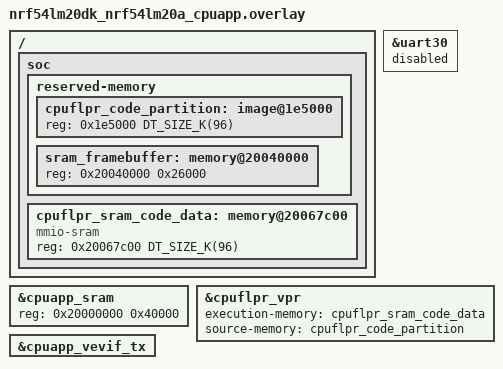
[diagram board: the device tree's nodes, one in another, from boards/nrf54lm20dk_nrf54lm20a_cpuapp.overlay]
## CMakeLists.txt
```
#
# Copyright (c) 2022 Nordic Semiconductor ASA
#
# SPDX-License-Identifier: LicenseRef-Nordic-5-Clause
#

cmake_minimum_required(VERSION 3.20.0)

find_package(Zephyr REQUIRED HINTS $ENV{ZEPHYR_BASE})
project(displaytest)

target_sources(app PRIVATE
    src/main.c
    src/render.c
    src/game.c
)

target_include_directories(app PRIVATE ${CMAKE_CURRENT_LIST_DIR}/../common)
```

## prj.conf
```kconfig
CONFIG_GPIO=y
CONFIG_SERIAL=y
CONFIG_CONSOLE=y
CONFIG_UART_CONSOLE=y

# Floating point support for game physics
CONFIG_FPU=y

# Increase main stack for game state + rendering
CONFIG_MAIN_STACK_SIZE=8192
```

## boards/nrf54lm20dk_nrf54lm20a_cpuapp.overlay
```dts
/*
 * CPU App overlay for nRF54LM20-DK Asteroids
 *
 * Based on the nordic-flpr snippet for nRF54LM20A, with additions
 * for the shared framebuffer region.
 *
 * Memory map:
 *   0x20000000 - 0x2003FFFF : CPUAPP SRAM (256KB) - kernel + game
 *   0x20040000 - 0x20065FFF : Shared framebuffer (155KB)
 *   0x20067C00 - 0x2007FBFF : FLPR SRAM (96KB) - display driver
 *
 *   0x001E5000 - 0x001FCFFF : FLPR code partition in RRAM (96KB)
 */

/ {
	soc {
		reserved-memory {
			#address-cells = <1>;
			#size-cells = <1>;

			/* FLPR firmware stored in RRAM (flash) - VPR launcher copies from here */
			cpuflpr_code_partition: image@1e5000 {
				reg = <0x1e5000 DT_SIZE_K(96)>;
			};

			/* Shared framebuffer between CPU and FLPR */
			sram_framebuffer: memory@20040000 {
				reg = <0x20040000 0x26000>;
			};
		};

		/* FLPR execution SRAM - VPR launcher loads code here */
		cpuflpr_sram_code_data: memory@20067c00 {
			compatible = "mmio-sram";
			reg = <0x20067c00 DT_SIZE_K(96)>;
			#address-cells = <1>;
			#size-cells = <1>;
			ranges = <0x0 0x20067c00 DT_SIZE_K(96)>;
		};
	};
};

/* Reduce CPUAPP SRAM: 256KB for kernel+game, rest is framebuffer + FLPR */
&cpuapp_sram {
	reg = <0x20000000 0x40000>;
	ranges = <0x0 0x20000000 0x40000>;
};

/* Reserve UART30 for FLPR console */
&uart30 {
	status = "reserved";
};

/* Enable FLPR core with memory configuration for VPR launcher */
&cpuflpr_vpr {
	status = "okay";
	execution-memory = <&cpuflpr_sram_code_data>;
	source-memory = <&cpuflpr_code_partition>;
};

/* Enable VEVIF TX for CPU->FLPR signaling (needed for VPR launcher) */
&cpuapp_vevif_tx {
	status = "okay";
};
```

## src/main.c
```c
/*
 * Asteroids - nRF54LM20-DK
 *
 * Main game loop on CPU (ARM Cortex-M33).
 * Interrupt-driven buttons, dirty-row framebuffer streaming via FLPR.
 */

#include <zephyr/kernel.h>
#include <zephyr/drivers/gpio.h>

#include "shared_display.h"
#include "game.h"
#include "render.h"

/* ------------------------------------------------------------------ */
/*  Interrupt-driven buttons                                          */
/* ------------------------------------------------------------------ */

static const struct gpio_dt_spec btn_specs[] = {
	GPIO_DT_SPEC_GET(DT_ALIAS(sw0), gpios),
	GPIO_DT_SPEC_GET(DT_ALIAS(sw1), gpios),
	GPIO_DT_SPEC_GET(DT_ALIAS(sw2), gpios),
	GPIO_DT_SPEC_GET(DT_ALIAS(sw3), gpios),
};

static struct gpio_callback btn_cb_data[4];
static volatile uint8_t button_state;

static void btn_isr(const struct device *dev, struct gpio_callback *cb, uint32_t pins)
{
	uint8_t state = 0;
	if (gpio_pin_get_dt(&btn_specs[0])) state |= BTN_THRUST;
	if (gpio_pin_get_dt(&btn_specs[1])) state |= BTN_LEFT;
	if (gpio_pin_get_dt(&btn_specs[2])) state |= BTN_RIGHT;
	if (gpio_pin_get_dt(&btn_specs[3])) state |= BTN_SHOOT;
	button_state = state;
}

static int init_buttons(void)
{
	for (int i = 0; i < ARRAY_SIZE(btn_specs); i++) {
		if (!gpio_is_ready_dt(&btn_specs[i])) {
			printk("ERROR: Button %d not ready\n", i);
			return -1;
		}
		int ret = gpio_pin_configure_dt(&btn_specs[i], GPIO_INPUT);
		if (ret < 0) return ret;

		ret = gpio_pin_interrupt_configure_dt(&btn_specs[i],
						      GPIO_INT_EDGE_BOTH);
		if (ret < 0) {
			printk("WARN: Button %d interrupt failed (%d), using polled\n", i, ret);
			continue;
		}

		gpio_init_callback(&btn_cb_data[i], btn_isr,
				   BIT(btn_specs[i].pin));
		gpio_add_callback(btn_specs[i].port, &btn_cb_data[i]);
	}
	return 0;
}

/* ------------------------------------------------------------------ */
/*  Display sync                                                      */
/* ------------------------------------------------------------------ */

static void wait_display_ready(void)
{
	printk("Waiting for FLPR...\n");
	while (SHARED_DISP->status == DISP_STATUS_INIT) {
		k_msleep(10);
	}
	printk("Display ready\n");
}

static void send_frame(void)
{
	/* Commit dirty bitmap to shared memory */
	render_commit_dirty();

	/* Memory barrier: ensure all framebuffer + dirty bitmap writes
	 * are committed before the FLPR sees FRAME_READY */
	__DSB();

	/* Signal FLPR */
	SHARED_DISP->status = DISP_STATUS_FRAME_READY;

	/* Tight spin — CPU has nothing else to do until FLPR finishes */
	while (SHARED_DISP->status != DISP_STATUS_READY) { }
}

/* ------------------------------------------------------------------ */
/*  Main                                                              */
/* ------------------------------------------------------------------ */

static struct game_state game;

int main(void)
{
	if (init_buttons() < 0) {
		return -1;
	}

	wait_display_ready();
	render_init(SHARED_DISP->framebuffer);
	render_set_mode(RMODE_PIXELS);  /* Change to RMODE_ROWS, RMODE_TILES or RMODE_PIXELS to test */
	game_init(&game);

	while (1) {
		uint32_t frame_start = k_uptime_get_32();

		uint8_t btns = button_state;
		game_update(&game, btns);
		game_render(&game);

		/* Measure CPU work time (game logic + rendering) */
		uint32_t work_ms = k_uptime_get_32() - frame_start;
		SHARED_DISP->cpu_work_us = (uint16_t)(work_ms * 1000);

		send_frame();

		uint32_t elapsed = k_uptime_get_32() - frame_start;
		if (elapsed < FRAME_TIME_MS) {
			k_msleep(FRAME_TIME_MS - elapsed);
		}
	}

	return 0;
}
```

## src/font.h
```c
/*
 * 8x8 bitmap font for retro game rendering.
 * Covers printable ASCII (space through tilde, 32-126).
 * Each glyph is 8 bytes, one byte per row, MSB = leftmost pixel.
 *
 * Index into font_8x8[ch - 32] to get the glyph for character ch.
 */

#ifndef FONT_H
#define FONT_H

#include <stdint.h>

/* 95 printable ASCII characters (32=' ' through 126='~') */
static const uint8_t font_8x8[95][8] = {
	/* 32 ' ' */ {0x00,0x00,0x00,0x00,0x00,0x00,0x00,0x00},
	/* 33 '!' */ {0x18,0x18,0x18,0x18,0x18,0x00,0x18,0x00},
	/* 34 '"' */ {0x6C,0x6C,0x6C,0x00,0x00,0x00,0x00,0x00},
	/* 35 '#' */ {0x6C,0x6C,0xFE,0x6C,0xFE,0x6C,0x6C,0x00},
	/* 36 '$' */ {0x18,0x7E,0xC0,0x7C,0x06,0xFC,0x18,0x00},
	/* 37 '%' */ {0x00,0xC6,0xCC,0x18,0x30,0x66,0xC6,0x00},
	/* 38 '&' */ {0x38,0x6C,0x38,0x76,0xDC,0xCC,0x76,0x00},
	/* 39 '\''*/ {0x18,0x18,0x30,0x00,0x00,0x00,0x00,0x00},
	/* 40 '(' */ {0x0C,0x18,0x30,0x30,0x30,0x18,0x0C,0x00},
	/* 41 ')' */ {0x30,0x18,0x0C,0x0C,0x0C,0x18,0x30,0x00},
	/* 42 '*' */ {0x00,0x66,0x3C,0xFF,0x3C,0x66,0x00,0x00},
	/* 43 '+' */ {0x00,0x18,0x18,0x7E,0x18,0x18,0x00,0x00},
	/* 44 ',' */ {0x00,0x00,0x00,0x00,0x00,0x18,0x18,0x30},
	/* 45 '-' */ {0x00,0x00,0x00,0x7E,0x00,0x00,0x00,0x00},
	/* 46 '.' */ {0x00,0x00,0x00,0x00,0x00,0x18,0x18,0x00},
	/* 47 '/' */ {0x06,0x0C,0x18,0x30,0x60,0xC0,0x80,0x00},
	/* 48 '0' */ {0x7C,0xC6,0xCE,0xDE,0xF6,0xE6,0x7C,0x00},
	/* 49 '1' */ {0x18,0x38,0x78,0x18,0x18,0x18,0x7E,0x00},
	/* 50 '2' */ {0x7C,0xC6,0x06,0x1C,0x30,0x66,0xFE,0x00},
	/* 51 '3' */ {0x7C,0xC6,0x06,0x3C,0x06,0xC6,0x7C,0x00},
	/* 52 '4' */ {0x1C,0x3C,0x6C,0xCC,0xFE,0x0C,0x1E,0x00},
	/* 53 '5' */ {0xFE,0xC0,0xFC,0x06,0x06,0xC6,0x7C,0x00},
	/* 54 '6' */ {0x38,0x60,0xC0,0xFC,0xC6,0xC6,0x7C,0x00},
	/* 55 '7' */ {0xFE,0xC6,0x0C,0x18,0x30,0x30,0x30,0x00},
	/* 56 '8' */ {0x7C,0xC6,0xC6,0x7C,0xC6,0xC6,0x7C,0x00},
	/* 57 '9' */ {0x7C,0xC6,0xC6,0x7E,0x06,0x0C,0x78,0x00},
	/* 58 ':' */ {0x00,0x18,0x18,0x00,0x00,0x18,0x18,0x00},
	/* 59 ';' */ {0x00,0x18,0x18,0x00,0x00,0x18,0x18,0x30},
	/* 60 '<' */ {0x06,0x0C,0x18,0x30,0x18,0x0C,0x06,0x00},
	/* 61 '=' */ {0x00,0x00,0x7E,0x00,0x7E,0x00,0x00,0x00},
	/* 62 '>' */ {0x60,0x30,0x18,0x0C,0x18,0x30,0x60,0x00},
	/* 63 '?' */ {0x7C,0xC6,0x0C,0x18,0x18,0x00,0x18,0x00},
	/* 64 '@' */ {0x7C,0xC6,0xDE,0xDE,0xDE,0xC0,0x78,0x00},
	/* 65 'A' */ {0x38,0x6C,0xC6,0xC6,0xFE,0xC6,0xC6,0x00},
	/* 66 'B' */ {0xFC,0x66,0x66,0x7C,0x66,0x66,0xFC,0x00},
	/* 67 'C' */ {0x3C,0x66,0xC0,0xC0,0xC0,0x66,0x3C,0x00},
	/* 68 'D' */ {0xF8,0x6C,0x66,0x66,0x66,0x6C,0xF8,0x00},
	/* 69 'E' */ {0xFE,0x62,0x68,0x78,0x68,0x62,0xFE,0x00},
	/* 70 'F' */ {0xFE,0x62,0x68,0x78,0x68,0x60,0xF0,0x00},
	/* 71 'G' */ {0x3C,0x66,0xC0,0xC0,0xCE,0x66,0x3E,0x00},
	/* 72 'H' */ {0xC6,0xC6,0xC6,0xFE,0xC6,0xC6,0xC6,0x00},
	/* 73 'I' */ {0x3C,0x18,0x18,0x18,0x18,0x18,0x3C,0x00},
	/* 74 'J' */ {0x1E,0x0C,0x0C,0x0C,0xCC,0xCC,0x78,0x00},
	/* 75 'K' */ {0xE6,0x66,0x6C,0x78,0x6C,0x66,0xE6,0x00},
	/* 76 'L' */ {0xF0,0x60,0x60,0x60,0x62,0x66,0xFE,0x00},
	/* 77 'M' */ {0xC6,0xEE,0xFE,0xD6,0xC6,0xC6,0xC6,0x00},
	/* 78 'N' */ {0xC6,0xE6,0xF6,0xDE,0xCE,0xC6,0xC6,0x00},
	/* 79 'O' */ {0x7C,0xC6,0xC6,0xC6,0xC6,0xC6,0x7C,0x00},
	/* 80 'P' */ {0xFC,0x66,0x66,0x7C,0x60,0x60,0xF0,0x00},
	/* 81 'Q' */ {0x7C,0xC6,0xC6,0xC6,0xD6,0xDE,0x7C,0x06},
	/* 82 'R' */ {0xFC,0x66,0x66,0x7C,0x6C,0x66,0xE6,0x00},
	/* 83 'S' */ {0x7C,0xC6,0xE0,0x7C,0x0E,0xC6,0x7C,0x00},
	/* 84 'T' */ {0x7E,0x5A,0x18,0x18,0x18,0x18,0x3C,0x00},
	/* 85 'U' */ {0xC6,0xC6,0xC6,0xC6,0xC6,0xC6,0x7C,0x00},
	/* 86 'V' */ {0xC6,0xC6,0xC6,0xC6,0x6C,0x38,0x10,0x00},
	/* 87 'W' */ {0xC6,0xC6,0xC6,0xD6,0xFE,0xEE,0xC6,0x00},
	/* 88 'X' */ {0xC6,0xC6,0x6C,0x38,0x6C,0xC6,0xC6,0x00},
	/* 89 'Y' */ {0x66,0x66,0x66,0x3C,0x18,0x18,0x3C,0x00},
	/* 90 'Z' */ {0xFE,0xC6,0x8C,0x18,0x32,0x66,0xFE,0x00},
	/* 91 '[' */ {0x3C,0x30,0x30,0x30,0x30,0x30,0x3C,0x00},
	/* 92 '\\'*/ {0xC0,0x60,0x30,0x18,0x0C,0x06,0x02,0x00},
	/* 93 ']' */ {0x3C,0x0C,0x0C,0x0C,0x0C,0x0C,0x3C,0x00},
	/* 94 '^' */ {0x10,0x38,0x6C,0xC6,0x00,0x00,0x00,0x00},
	/* 95 '_' */ {0x00,0x00,0x00,0x00,0x00,0x00,0x00,0xFF},
	/* 96 '`' */ {0x30,0x18,0x0C,0x00,0x00,0x00,0x00,0x00},
	/* 97 'a' */ {0x00,0x00,0x78,0x0C,0x7C,0xCC,0x76,0x00},
	/* 98 'b' */ {0xE0,0x60,0x7C,0x66,0x66,0x66,0xDC,0x00},
	/* 99 'c' */ {0x00,0x00,0x7C,0xC6,0xC0,0xC6,0x7C,0x00},
	/*100 'd' */ {0x1C,0x0C,0x7C,0xCC,0xCC,0xCC,0x76,0x00},
	/*101 'e' */ {0x00,0x00,0x7C,0xC6,0xFE,0xC0,0x7C,0x00},
	/*102 'f' */ {0x1C,0x36,0x30,0x78,0x30,0x30,0x78,0x00},
	/*103 'g' */ {0x00,0x00,0x76,0xCC,0xCC,0x7C,0x0C,0xF8},
	/*104 'h' */ {0xE0,0x60,0x6C,0x76,0x66,0x66,0xE6,0x00},
	/*105 'i' */ {0x18,0x00,0x38,0x18,0x18,0x18,0x3C,0x00},
	/*106 'j' */ {0x06,0x00,0x06,0x06,0x06,0x66,0x66,0x3C},
	/*107 'k' */ {0xE0,0x60,0x66,0x6C,0x78,0x6C,0xE6,0x00},
	/*108 'l' */ {0x38,0x18,0x18,0x18,0x18,0x18,0x3C,0x00},
	/*109 'm' */ {0x00,0x00,0xEC,0xFE,0xD6,0xC6,0xC6,0x00},
	/*110 'n' */ {0x00,0x00,0xDC,0x66,0x66,0x66,0x66,0x00},
	/*111 'o' */ {0x00,0x00,0x7C,0xC6,0xC6,0xC6,0x7C,0x00},
	/*112 'p' */ {0x00,0x00,0xDC,0x66,0x66,0x7C,0x60,0xF0},
	/*113 'q' */ {0x00,0x00,0x76,0xCC,0xCC,0x7C,0x0C,0x1E},
	/*114 'r' */ {0x00,0x00,0xDC,0x76,0x60,0x60,0xF0,0x00},
	/*115 's' */ {0x00,0x00,0x7C,0xC0,0x7C,0x06,0xFC,0x00},
	/*116 't' */ {0x30,0x30,0x7C,0x30,0x30,0x36,0x1C,0x00},
	/*117 'u' */ {0x00,0x00,0xCC,0xCC,0xCC,0xCC,0x76,0x00},
	/*118 'v' */ {0x00,0x00,0xC6,0xC6,0x6C,0x38,0x10,0x00},
	/*119 'w' */ {0x00,0x00,0xC6,0xC6,0xD6,0xFE,0x6C,0x00},
	/*120 'x' */ {0x00,0x00,0xC6,0x6C,0x38,0x6C,0xC6,0x00},
	/*121 'y' */ {0x00,0x00,0xC6,0xC6,0xCE,0x76,0x06,0xFC},
	/*122 'z' */ {0x00,0x00,0xFC,0x98,0x30,0x64,0xFC,0x00},
	/*123 '{' */ {0x0E,0x18,0x18,0x70,0x18,0x18,0x0E,0x00},
	/*124 '|' */ {0x18,0x18,0x18,0x00,0x18,0x18,0x18,0x00},
	/*125 '}' */ {0x70,0x18,0x18,0x0E,0x18,0x18,0x70,0x00},
	/*126 '~' */ {0x76,0xDC,0x00,0x00,0x00,0x00,0x00,0x00},
};

#endif /* FONT_H */
```

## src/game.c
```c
/*
 * Asteroids game logic and rendering.
 * Pure game code - no hardware dependencies.
 */

#include <string.h>
#include "game.h"
#include "render.h"

/* Precomputed float sin/cos tables */
static float sin_table[DEG_COUNT];
static float cos_table[DEG_COUNT];
static bool trig_initialized;

/* No more precomputed R2 defines — stored per-asteroid at spawn time */

/* Precomputed vertex angle step */
#define VERT_STEP (360.0f / ASTEROID_VERTICES)

/* Half-world constants for wrapping (avoid repeated division) */
#define HALF_W (WORLD_W / 2)
#define HALF_H (WORLD_H / 2)

/* ------------------------------------------------------------------ */
/*  PRNG                                                              */
/* ------------------------------------------------------------------ */

static inline uint32_t rng_next(struct game_state *g)
{
	uint32_t x = g->rng;
	x ^= x << 13;
	x ^= x >> 17;
	x ^= x << 5;
	g->rng = x;
	return x;
}

static inline float rng_float(struct game_state *g, float lo, float hi)
{
	return lo + (float)(rng_next(g) & 0xFFFF) * (1.0f / 65536.0f) * (hi - lo);
}

static inline int rng_int(struct game_state *g, int lo, int hi)
{
	return lo + (int)(rng_next(g) % (uint32_t)(hi - lo + 1));
}

/* ------------------------------------------------------------------ */
/*  Trig (inlined lookups, no function call overhead)                 */
/* ------------------------------------------------------------------ */

static void init_trig(void)
{
	if (trig_initialized) return;

	for (int d = 0; d < DEG_COUNT; d++) {
		float rad = (float)d * (3.14159265f / 180.0f);
		float x = rad;
		float x2 = x * x;
		float x3 = x2 * x;
		float x5 = x3 * x2;
		float x7 = x5 * x2;
		float s = x - x3 / 6.0f + x5 / 120.0f - x7 / 5040.0f;
		if (s > 1.0f) s = 1.0f;
		if (s < -1.0f) s = -1.0f;
		sin_table[d] = s;
	}
	for (int d = 0; d < DEG_COUNT; d++) {
		cos_table[d] = sin_table[(d + 90) % DEG_COUNT];
	}
	trig_initialized = true;
}

/* Branchless angle index: handles negatives without conditional */
static inline int angle_idx(float deg)
{
	int d = (int)deg % DEG_COUNT;
	return d + (DEG_COUNT & (d >> 31)); /* add 360 if negative */
}

static inline float fsin(float deg) { return sin_table[angle_idx(deg)]; }
static inline float fcos(float deg) { return cos_table[angle_idx(deg)]; }

/* ------------------------------------------------------------------ */
/*  Wrapping (if, not while — entities never overshoot by >1 world)   */
/* ------------------------------------------------------------------ */

static inline void wrap_pos(struct vec2 *p)
{
	if (p->x < 0) p->x += WORLD_W;
	else if (p->x >= WORLD_W) p->x -= WORLD_W;
	if (p->y < 0) p->y += WORLD_H;
	else if (p->y >= WORLD_H) p->y -= WORLD_H;
}

/* ------------------------------------------------------------------ */
/*  World-to-screen (inlined)                                         */
/* ------------------------------------------------------------------ */

static inline int to_sx(float wx, float cx)
{
	float dx = wx - cx;
	if (dx > HALF_W) dx -= WORLD_W;
	else if (dx < -HALF_W) dx += WORLD_W;
	return (int)dx + SCREEN_W / 2;
}

static inline int to_sy(float wy, float cy)
{
	float dy = wy - cy;
	if (dy > HALF_H) dy -= WORLD_H;
	else if (dy < -HALF_H) dy += WORLD_H;
	return (int)dy + SCREEN_H / 2;
}

static inline bool on_screen(int sx, int sy, int margin)
{
	return (unsigned)(sx + margin) < (unsigned)(SCREEN_W + 2 * margin) &&
	       (unsigned)(sy + margin) < (unsigned)(SCREEN_H + 2 * margin);
}

/* ------------------------------------------------------------------ */
/*  Collision — ALL INTEGER, no float in the hot path                 */
/*  Truncate positions to int, integer wrapping, manhattan reject,    */
/*  integer distance squared. ~6 cycles for the 90% rejection case.  */
/* ------------------------------------------------------------------ */

static inline bool hit_test(struct vec2 a, struct vec2 b, int r, int r_sq)
{
	int dx = (int)a.x - (int)b.x;
	int dy = (int)a.y - (int)b.y;

	/* Integer wrapping */
	if (dx > HALF_W) dx -= WORLD_W;
	else if (dx < -HALF_W) dx += WORLD_W;
	if (dy > HALF_H) dy -= WORLD_H;
	else if (dy < -HALF_H) dy += WORLD_H;

	/* Manhattan early-out with tight radius (not hardcoded 40) */
	if (dx > r || dx < -r || dy > r || dy < -r) {
		return false;
	}

	return dx * dx + dy * dy < r_sq;
}

/* Float version only used for spawn distance check (called rarely) */
static inline float dist_sq_f(struct vec2 a, struct vec2 b)
{
	float dx = a.x - b.x;
	float dy = a.y - b.y;
	if (dx > HALF_W) dx -= WORLD_W;
	else if (dx < -HALF_W) dx += WORLD_W;
	if (dy > HALF_H) dy -= WORLD_H;
	else if (dy < -HALF_H) dy += WORLD_H;
	return dx * dx + dy * dy;
}

/* ------------------------------------------------------------------ */
/*  Spawning                                                          */
/* ------------------------------------------------------------------ */

static void spawn_particles(struct game_state *g, struct vec2 pos, int count)
{
	for (int i = 0; i < MAX_PARTICLES && count > 0; i++) {
		if (g->particles[i].life > 0) continue;
		struct particle *p = &g->particles[i];
		p->pos = pos;
		float angle = rng_float(g, 0, 360);
		float speed = rng_float(g, 0.5f, PARTICLE_SPEED);
		p->vel.x = fcos(angle) * speed;
		p->vel.y = fsin(angle) * speed;
		p->life = rng_int(g, PARTICLE_LIFE_MIN, PARTICLE_LIFE_MAX);
		p->color = rng_int(g, COLOR_RED, COLOR_ORANGE);
		count--;
	}
}

static void spawn_asteroid(struct game_state *g, int size, float x, float y)
{
	for (int i = 0; i < MAX_ASTEROIDS; i++) {
		if (g->asteroids[i].size != 0) continue;
		struct asteroid *a = &g->asteroids[i];
		a->pos.x = x;
		a->pos.y = y;
		a->size = size;
		int r = (size == 1) ? ASTEROID_LARGE_R : ASTEROID_SMALL_R;
		a->radius = r;
		int br = r + BULLET_RADIUS;
		int sr = r + SHIP_RADIUS;
		a->bullet_r2 = br * br;
		a->ship_r2 = sr * sr;
		a->shape_seed = (uint8_t)(rng_next(g) & 0xFF);
		float angle = rng_float(g, 0, 360);
		float speed = rng_float(g, ASTEROID_SPEED_MIN, ASTEROID_SPEED_MAX);
		if (size == 2) speed *= 1.5f;
		a->vel.x = fcos(angle) * speed;
		a->vel.y = fsin(angle) * speed;
		a->angle = rng_float(g, 0, 360);
		a->spin = rng_float(g, -2.0f, 2.0f);
		g->active_asteroids++;
		return;
	}
}

static void spawn_wave(struct game_state *g)
{
	g->wave++;
	int count = INITIAL_ASTEROIDS + (g->wave - 1) * WAVE_EXTRA;
	if (count > MAX_ASTEROIDS) count = MAX_ASTEROIDS;

	for (int i = 0; i < count; i++) {
		float x, y;
		do {
			x = rng_float(g, 0, WORLD_W);
			y = rng_float(g, 0, WORLD_H);
		} while (dist_sq_f((struct vec2){x, y}, g->ship.pos) < 150.0f * 150.0f);
		spawn_asteroid(g, 1, x, y);
	}
}

/* count_active_asteroids: just return cached value */
static inline int count_active_asteroids(struct game_state *g)
{
	return g->active_asteroids;
}

/* ------------------------------------------------------------------ */
/*  Stars                                                             */
/* ------------------------------------------------------------------ */

static void generate_stars(struct game_state *g)
{
	uint32_t saved_rng = g->rng;
	g->rng = 0xDEADBEEF;
	for (int i = 0; i < NUM_STARS; i++) {
		g->stars[i].x = rng_int(g, 0, WORLD_W - 1);
		g->stars[i].y = rng_int(g, 0, WORLD_H - 1);
	}
	g->rng = saved_rng;
}

/* ------------------------------------------------------------------ */
/*  Init                                                              */
/* ------------------------------------------------------------------ */

void game_init(struct game_state *g)
{
	init_trig();
	memset(g, 0, sizeof(*g));
	g->screen = SCREEN_TITLE;
	g->prev_screen = SCREEN_TITLE;
	g->rng = 12345678;
	g->ship.pos.x = WORLD_W / 2;
	g->ship.pos.y = WORLD_H / 2;
	g->ship.angle = 270;
	generate_stars(g);
}

static void start_game(struct game_state *g, uint32_t seed)
{
	struct star saved_stars[NUM_STARS];
	memcpy(saved_stars, g->stars, sizeof(saved_stars));

	uint32_t rng = g->rng ^ seed;
	enum game_screen old_screen = g->screen;
	memset(g, 0, sizeof(*g));
	g->rng = rng ? rng : 42;
	g->screen = SCREEN_PLAY;
	g->prev_screen = old_screen;
	memcpy(g->stars, saved_stars, sizeof(saved_stars));

	g->ship.pos.x = WORLD_W / 2;
	g->ship.pos.y = WORLD_H / 2;
	g->ship.angle = 270;
	g->wave = 0;
	spawn_wave(g);
}

/* ------------------------------------------------------------------ */
/*  Update                                                            */
/* ------------------------------------------------------------------ */

void game_update(struct game_state *g, uint8_t buttons)
{
	g->frame++;

#if BENCHMARK_MODE
	/* Auto-start, skip title/death screens */
	if (g->screen != SCREEN_PLAY) {
		start_game(g, g->frame);
	}
#else
	switch (g->screen) {
	case SCREEN_TITLE:
		if (buttons & BTN_SHOOT) start_game(g, g->frame);
		return;
	case SCREEN_DEAD:
		if (g->death_timer > 0) g->death_timer--;
		else if (buttons & BTN_SHOOT) start_game(g, g->frame);
		return;
	case SCREEN_PLAY:
		break;
	}
#endif

	/* Ship rotation */
	if (buttons & BTN_LEFT) {
		g->ship.angle -= SHIP_ROTATE_SPEED;
		if (g->ship.angle < 0) g->ship.angle += 360;
	}
	if (buttons & BTN_RIGHT) {
		g->ship.angle += SHIP_ROTATE_SPEED;
		if (g->ship.angle >= 360) g->ship.angle -= 360;
	}

	/* Ship thrust */
	g->ship.thrusting = (buttons & BTN_THRUST) != 0;
	if (g->ship.thrusting) {
		float ca = fcos(g->ship.angle);
		float sa = fsin(g->ship.angle);
		g->ship.vel.x += ca * SHIP_THRUST;
		g->ship.vel.y += sa * SHIP_THRUST;

		float spd2 = g->ship.vel.x * g->ship.vel.x +
			     g->ship.vel.y * g->ship.vel.y;
		if (spd2 > SHIP_MAX_SPEED * SHIP_MAX_SPEED) {
			g->ship.vel.x *= 0.97f;
			g->ship.vel.y *= 0.97f;
		}
	}

	/* Ship movement */
	g->ship.pos.x += g->ship.vel.x;
	g->ship.pos.y += g->ship.vel.y;
	wrap_pos(&g->ship.pos);

#if !BENCHMARK_MODE
	/* Shooting */
	if ((buttons & BTN_SHOOT) && (g->frame % 8) == 0) {
		float ca = fcos(g->ship.angle);
		float sa = fsin(g->ship.angle);
		for (int i = 0; i < MAX_BULLETS; i++) {
			if (g->bullets[i].life > 0) continue;
			struct bullet *b = &g->bullets[i];
			b->pos.x = g->ship.pos.x + ca * SHIP_RADIUS;
			b->pos.y = g->ship.pos.y + sa * SHIP_RADIUS;
			b->vel.x = ca * BULLET_SPEED + g->ship.vel.x * 0.5f;
			b->vel.y = sa * BULLET_SPEED + g->ship.vel.y * 0.5f;
			b->life = BULLET_LIFETIME;
			break;
		}
	}
#endif

	/* Update bullets */
	for (int i = 0; i < MAX_BULLETS; i++) {
		struct bullet *b = &g->bullets[i];
		if (b->life <= 0) continue;
		b->pos.x += b->vel.x;
		b->pos.y += b->vel.y;
		wrap_pos(&b->pos);
		b->life--;
	}

	/* Update asteroids */
	for (int i = 0; i < MAX_ASTEROIDS; i++) {
		struct asteroid *a = &g->asteroids[i];
		if (a->size == 0) continue;
		a->pos.x += a->vel.x;
		a->pos.y += a->vel.y;
		wrap_pos(&a->pos);
		a->angle += a->spin;
		if (a->angle >= 360) a->angle -= 360;
		if (a->angle < 0) a->angle += 360;
	}

	/* Update particles */
	for (int i = 0; i < MAX_PARTICLES; i++) {
		struct particle *p = &g->particles[i];
		if (p->life <= 0) continue;
		p->pos.x += p->vel.x;
		p->pos.y += p->vel.y;
		p->vel.x *= 0.95f;
		p->vel.y *= 0.95f;
		p->life--;
	}

#if !BENCHMARK_MODE
	/* Bullet-asteroid collisions (pure integer hit_test) */
	for (int bi = 0; bi < MAX_BULLETS; bi++) {
		struct bullet *b = &g->bullets[bi];
		if (b->life <= 0) continue;

		for (int ai = 0; ai < MAX_ASTEROIDS; ai++) {
			struct asteroid *a = &g->asteroids[ai];
			if (a->size == 0) continue;

			if (hit_test(b->pos, a->pos,
				     a->radius + BULLET_RADIUS, a->bullet_r2)) {
				b->life = 0;
				spawn_particles(g, a->pos, 8);
				if (a->size == 1) {
					g->score += SCORE_LARGE;
					float ax = a->pos.x, ay = a->pos.y;
					a->size = 0;
					g->active_asteroids--;
					spawn_asteroid(g, 2, ax, ay);
					spawn_asteroid(g, 2, ax, ay);
				} else {
					g->score += SCORE_SMALL;
					a->size = 0;
					g->active_asteroids--;
				}
				break;
			}
		}
	}

	/* Ship-asteroid collisions */
	for (int i = 0; i < MAX_ASTEROIDS; i++) {
		struct asteroid *a = &g->asteroids[i];
		if (a->size == 0) continue;

		if (hit_test(g->ship.pos, a->pos,
			     a->radius + SHIP_RADIUS, a->ship_r2)) {
			spawn_particles(g, g->ship.pos, 16);
			g->screen = SCREEN_DEAD;
			g->death_timer = 60;
			return;
		}
	}
#endif /* !BENCHMARK_MODE */

	/* Spawn new wave */
	if (g->active_asteroids == 0) {
		spawn_wave(g);
	}
}

/* ------------------------------------------------------------------ */
/*  Rendering                                                         */
/* ------------------------------------------------------------------ */

static void render_ship(struct game_state *g, float cam_x, float cam_y)
{
	float a = g->ship.angle;
	int sx = to_sx(g->ship.pos.x, cam_x);
	int sy = to_sy(g->ship.pos.y, cam_y);

	/* Cache trig for the base angle — derive the others from offsets */
	int nose_x  = sx + (int)(fcos(a) * SHIP_RADIUS);
	int nose_y  = sy + (int)(fsin(a) * SHIP_RADIUS);
	int left_x  = sx + (int)(fcos(a + 140) * SHIP_RADIUS);
	int left_y  = sy + (int)(fsin(a + 140) * SHIP_RADIUS);
	int right_x = sx + (int)(fcos(a - 140) * SHIP_RADIUS);
	int right_y = sy + (int)(fsin(a - 140) * SHIP_RADIUS);

	render_line(nose_x, nose_y, left_x, left_y, COLOR_WHITE);
	render_line(left_x, left_y, right_x, right_y, COLOR_WHITE);
	render_line(right_x, right_y, nose_x, nose_y, COLOR_WHITE);

	if (g->ship.thrusting && (g->frame & 2)) {
		int tail_x = sx - (int)(fcos(a) * (SHIP_RADIUS + 6));
		int tail_y = sy - (int)(fsin(a) * (SHIP_RADIUS + 6));
		int bl_x   = sx + (int)(fcos(a + 160) * (SHIP_RADIUS - 3));
		int bl_y   = sy + (int)(fsin(a + 160) * (SHIP_RADIUS - 3));
		int br_x   = sx + (int)(fcos(a - 160) * (SHIP_RADIUS - 3));
		int br_y   = sy + (int)(fsin(a - 160) * (SHIP_RADIUS - 3));

		render_line(bl_x, bl_y, tail_x, tail_y, COLOR_ORANGE);
		render_line(tail_x, tail_y, br_x, br_y, COLOR_ORANGE);
	}
}

static void render_asteroid_shape(struct asteroid *a, int sx, int sy)
{
	int r = a->radius;
	int vx[ASTEROID_VERTICES];
	int vy[ASTEROID_VERTICES];

	uint8_t seed = a->shape_seed;
	float base_angle = a->angle;

	for (int i = 0; i < ASTEROID_VERTICES; i++) {
		float va = base_angle + (float)i * VERT_STEP;
		/* Vary radius: 70% or 100% based on seed bit */
		int vr = (seed & (1 << (i & 7))) ? r : (r * 7 / 10);
		vx[i] = sx + (int)(fcos(va) * vr);
		vy[i] = sy + (int)(fsin(va) * vr);
	}

	render_polygon(vx, vy, ASTEROID_VERTICES, COLOR_WHITE);
}

void game_render(struct game_state *g)
{
	if (g->screen != g->prev_screen) {
		render_full_clear();
		g->prev_screen = g->screen;
	} else {
		render_clear();
	}

	/* Camera */
	float cam_x, cam_y;
	if (g->screen == SCREEN_PLAY) {
		cam_x = g->ship.pos.x;
		cam_y = g->ship.pos.y;
	} else {
		cam_x = WORLD_W / 2;
		cam_y = WORLD_H / 2;
	}

	/* Stars */
	for (int i = 0; i < NUM_STARS; i++) {
		int sx = to_sx((float)g->stars[i].x, cam_x);
		int sy = to_sy((float)g->stars[i].y, cam_y);
		render_pixel(sx, sy, COLOR_WHITE);
	}

	switch (g->screen) {
	case SCREEN_TITLE:
		render_string_centered(120, "ASTEROIDS", COLOR_WHITE);
		render_string_centered(180, "PRESS FIRE TO START", COLOR_WHITE);
		return;
	case SCREEN_DEAD:
		render_string_centered(100, "GAME OVER", COLOR_RED);
		render_string_centered(150, "SCORE", COLOR_WHITE);
		render_number_centered(170, g->score, COLOR_YELLOW);
		if (g->death_timer <= 0)
			render_string_centered(220, "PRESS FIRE TO RESTART", COLOR_WHITE);
		return;
	case SCREEN_PLAY:
		break;
	}

	/* Asteroids — compute screen pos once, reuse for visibility + render */
	for (int i = 0; i < MAX_ASTEROIDS; i++) {
		struct asteroid *a = &g->asteroids[i];
		if (a->size == 0) continue;
		int sx = to_sx(a->pos.x, cam_x);
		int sy = to_sy(a->pos.y, cam_y);
		if (on_screen(sx, sy, a->radius + 5)) {
			render_asteroid_shape(a, sx, sy);
		}
	}

	/* Bullets */
	for (int i = 0; i < MAX_BULLETS; i++) {
		struct bullet *b = &g->bullets[i];
		if (b->life <= 0) continue;
		int sx = to_sx(b->pos.x, cam_x);
		int sy = to_sy(b->pos.y, cam_y);
		if (on_screen(sx, sy, 4)) {
			render_circle_filled(sx, sy, BULLET_RADIUS, COLOR_WHITE);
		}
	}

	/* Particles */
	for (int i = 0; i < MAX_PARTICLES; i++) {
		struct particle *p = &g->particles[i];
		if (p->life <= 0) continue;
		int sx = to_sx(p->pos.x, cam_x);
		int sy = to_sy(p->pos.y, cam_y);
		if (on_screen(sx, sy, 4)) {
			render_pixel(sx, sy, p->color);
			render_pixel(sx + 1, sy, p->color);
			render_pixel(sx, sy + 1, p->color);
			render_pixel(sx + 1, sy + 1, p->color);
		}
	}

	/* Ship */
	render_ship(g, cam_x, cam_y);

	/* HUD - all text inset from edges to avoid bezel clipping */
	int hx = 16;  /* left margin */
	int hy = 24;  /* top margin */

	/* Row 1: score */
	render_string(hx, hy, "SCORE:", COLOR_WHITE);
	render_number(hx + 48, hy, g->score, COLOR_WHITE);

	/* Row 2: wave, asteroids, FPS */
	render_string(hx, hy + 12, "W:", COLOR_WHITE);
	render_number(hx + 16, hy + 12, g->wave, COLOR_WHITE);
	render_string(hx + 48, hy + 12, "A:", COLOR_WHITE);
	render_number(hx + 64, hy + 12, count_active_asteroids(g), COLOR_WHITE);

	uint16_t fps = SHARED_DISP->fps;
	if (fps > 0) {
		render_number(FB_WIDTH - 52, hy + 12, fps, COLOR_WHITE);
		render_string(FB_WIDTH - 28, hy + 12, "FP", COLOR_WHITE);
	}

	/* Row 3: CPU% and DSP% */
	uint16_t cpu_us = SHARED_DISP->cpu_work_us;
	uint16_t flpr_us = SHARED_DISP->flpr_stream_us;
	int cpu_pct = (cpu_us + 165) / 330;
	int flpr_pct = (flpr_us + 165) / 330;

	render_string(hx, hy + 24, "CPU:", COLOR_WHITE);
	render_number(hx + 32, hy + 24, cpu_pct, COLOR_WHITE);
	render_char(hx + 32 + 8 * (cpu_pct >= 100 ? 3 : cpu_pct >= 10 ? 2 : 1), hy + 24, '%', COLOR_WHITE);

	render_string(hx + 96, hy + 24, "DSP:", COLOR_WHITE);
	render_number(hx + 128, hy + 24, flpr_pct, COLOR_WHITE);
	render_char(hx + 128 + 8 * (flpr_pct >= 100 ? 3 : flpr_pct >= 10 ? 2 : 1), hy + 24, '%', COLOR_WHITE);

	/* Mode label */
	const char *mode_name;
	switch (SHARED_DISP->render_mode) {
	case RMODE_TILES:  mode_name = "R:TILE"; break;
	case RMODE_PIXELS: mode_name = "R:PIX";  break;
	default:           mode_name = "R:ROW";  break;
	}
	render_string(FB_WIDTH - 60, hy + 24, mode_name, COLOR_WHITE);
}
```

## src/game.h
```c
#ifndef GAME_H
#define GAME_H

#include <stdint.h>
#include <stdbool.h>
#include "shared_display.h"

/* --- Screen & World --- */
#define SCREEN_W        FB_WIDTH    /* 480 */
#define SCREEN_H        FB_HEIGHT   /* 320 */
#define WORLD_W         960
#define WORLD_H         640

/* --- Limits --- */
#define MAX_ASTEROIDS   24
#define MAX_BULLETS     8
#define MAX_PARTICLES   48

/* --- Tuning --- */
#define SHIP_THRUST         0.12f
#define SHIP_MAX_SPEED      5.0f
#define SHIP_ROTATE_SPEED   5.0f    /* degrees per frame */
#define SHIP_RADIUS         10

#define BULLET_SPEED        7.0f
#define BULLET_LIFETIME     60      /* frames (~2 sec) */
#define BULLET_RADIUS       2

#define ASTEROID_LARGE_R    25
#define ASTEROID_SMALL_R    12
#define ASTEROID_SPEED_MIN  0.3f
#define ASTEROID_SPEED_MAX  1.5f
#define ASTEROID_VERTICES   8       /* vertices per asteroid shape */

#define PARTICLE_LIFE_MIN   8
#define PARTICLE_LIFE_MAX   20
#define PARTICLE_SPEED      3.0f

#define SCORE_LARGE         10
#define SCORE_SMALL         20

#define INITIAL_ASTEROIDS   10
#define WAVE_EXTRA          2       /* extra asteroids each wave */

#define FRAME_TIME_MS       33      /* ~30 fps */

/* Set to 1 to disable collisions/death for display stress testing */
#define BENCHMARK_MODE      0

#define NUM_STARS           50      /* sparse background stars */

/* Fixed-point trig: we precompute sin/cos tables for integer degrees */
#define DEG_COUNT 360

/* --- Types --- */

struct vec2 {
	float x;
	float y;
};

enum game_screen {
	SCREEN_TITLE,
	SCREEN_PLAY,
	SCREEN_DEAD,
};

struct ship {
	struct vec2 pos;
	struct vec2 vel;
	float angle;            /* degrees, 0 = right */
	bool thrusting;
};

struct asteroid {
	struct vec2 pos;
	struct vec2 vel;
	float angle;
	float spin;             /* degrees per frame rotation */
	int size;               /* 0=inactive, 1=large, 2=small */
	int radius;             /* cached from size */
	int bullet_r2;          /* (radius + BULLET_RADIUS)^2, precomputed */
	int ship_r2;            /* (radius + SHIP_RADIUS)^2, precomputed */
	uint8_t shape_seed;
};

struct bullet {
	struct vec2 pos;
	struct vec2 vel;
	int life;               /* frames remaining; 0=inactive */
};

struct particle {
	struct vec2 pos;
	struct vec2 vel;
	int life;               /* frames remaining; 0=inactive */
	uint8_t color;          /* palette index */
};

struct star {
	int16_t x;  /* screen-space, fixed */
	int16_t y;
};

struct game_state {
	enum game_screen screen;
	enum game_screen prev_screen; /* for detecting transitions */
	struct ship ship;
	struct asteroid asteroids[MAX_ASTEROIDS];
	struct bullet bullets[MAX_BULLETS];
	struct particle particles[MAX_PARTICLES];
	struct star stars[NUM_STARS];
	int score;
	int wave;
	int active_asteroids;   /* cached count, updated on spawn/destroy */
	uint32_t frame;         /* frame counter */
	uint32_t rng;           /* simple PRNG state */
	int death_timer;        /* delay before allowing restart */
};

/* Button state bitmask */
#define BTN_THRUST  (1 << 0)
#define BTN_LEFT    (1 << 1)
#define BTN_RIGHT   (1 << 2)
#define BTN_SHOOT   (1 << 3)

/* --- API --- */
void game_init(struct game_state *g);
void game_update(struct game_state *g, uint8_t buttons);
void game_render(struct game_state *g);

#endif /* GAME_H */
```

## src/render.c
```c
/*
 * Software rendering engine with pluggable dirty tracking.
 *
 * Three modes:
 *   RMODE_ROWS   — track dirty rows, stream full 480px per row (default)
 *   RMODE_TILES  — track dirty 16×16 tiles, stream per-tile
 *   RMODE_PIXELS — track per-row x_min/x_max span, stream clipped rows
 *
 * All modes also maintain the row bitmap for y_min/y_max hints.
 */

#include <string.h>
#include <stdlib.h>
#include "render.h"
#include "font.h"

static uint8_t *fb;
static uint8_t mode = RMODE_ROWS;

/* --- Row tracking (all modes use this for y extents) --- */
static uint32_t last_dirty[DIRTY_WORDS];
static int last_y_min, last_y_max;
static uint32_t dirty[DIRTY_WORDS];
static int dirty_y_min, dirty_y_max;

/* --- Tile tracking (mode 1) --- */
static uint32_t last_tiles[TILE_WORDS];
static uint32_t cur_tiles[TILE_WORDS];

/* --- Span tracking (mode 2) --- */
static struct row_span last_spans[FB_HEIGHT];
static struct row_span cur_spans[FB_HEIGHT];

/* ------------------------------------------------------------------ */
/*  Mark helpers                                                      */
/* ------------------------------------------------------------------ */

static inline void mark_row(int y)
{
	dirty[y >> 5] |= (1U << (y & 31));
	if (y < dirty_y_min) dirty_y_min = y;
	if (y > dirty_y_max) dirty_y_max = y;
}

static inline void mark_tile(int x, int y)
{
	int idx = (y / TILE_H) * TILES_X + (x / TILE_W);
	cur_tiles[idx >> 5] |= (1U << (idx & 31));
}

static inline void mark_span(int x, int y)
{
	struct row_span *s = &cur_spans[y];
	if (x < s->x_min) s->x_min = x;
	if (x > s->x_max) s->x_max = x;
}

static inline void mark_dirty(int x, int y)
{
	mark_row(y);
	if (mode == RMODE_TILES) {
		mark_tile(x, y);
	} else if (mode == RMODE_PIXELS) {
		mark_span(x, y);
	}
}

/* ------------------------------------------------------------------ */
/*  Init / Mode                                                       */
/* ------------------------------------------------------------------ */

void render_init(uint8_t *framebuffer)
{
	fb = framebuffer;
	memset(last_dirty, 0, sizeof(last_dirty));
	memset(dirty, 0, sizeof(dirty));
	memset(last_tiles, 0, sizeof(last_tiles));
	memset(cur_tiles, 0, sizeof(cur_tiles));
	for (int i = 0; i < FB_HEIGHT; i++) {
		last_spans[i].x_min = FB_WIDTH;
		last_spans[i].x_max = 0;
		cur_spans[i].x_min = FB_WIDTH;
		cur_spans[i].x_max = 0;
	}
	last_y_min = FB_HEIGHT;
	last_y_max = -1;
	dirty_y_min = FB_HEIGHT;
	dirty_y_max = -1;
}

void render_set_mode(uint8_t m)
{
	mode = m;
	SHARED_DISP->render_mode = m;
}

/* ------------------------------------------------------------------ */
/*  Clear                                                             */
/* ------------------------------------------------------------------ */

void render_clear(void)
{
	switch (mode) {
	case RMODE_ROWS:
		/* Clear full rows that were drawn last frame */
		for (int w = 0; w < DIRTY_WORDS; w++) {
			uint32_t bits = last_dirty[w];
			while (bits) {
				int bit = __builtin_ctz(bits);
				int y = (w << 5) | bit;
				if (y < FB_HEIGHT)
					memset(&fb[y * FB_WIDTH], 0, FB_WIDTH);
				bits &= bits - 1;
			}
		}
		break;

	case RMODE_TILES:
		/* Clear only tiles that were drawn last frame */
		for (int w = 0; w < TILE_WORDS; w++) {
			uint32_t bits = last_tiles[w];
			while (bits) {
				int bit = __builtin_ctz(bits);
				int idx = (w << 5) | bit;
				if (idx < TILE_COUNT) {
					int tx = (idx % TILES_X) * TILE_W;
					int ty = (idx / TILES_X) * TILE_H;
					for (int r = 0; r < TILE_H && ty + r < FB_HEIGHT; r++) {
						memset(&fb[(ty + r) * FB_WIDTH + tx], 0, TILE_W);
					}
				}
				bits &= bits - 1;
			}
		}
		break;

	case RMODE_PIXELS:
		/* Clear only the span of each row that was drawn last frame */
		for (int y = last_y_min; y <= last_y_max && y < FB_HEIGHT; y++) {
			struct row_span *s = &last_spans[y];
			if (s->x_min <= s->x_max && s->x_max < FB_WIDTH) {
				memset(&fb[y * FB_WIDTH + s->x_min], 0,
				       s->x_max - s->x_min + 1);
			}
		}
		break;
	}

	/* Reset current dirty state */
	memset(dirty, 0, sizeof(dirty));
	dirty_y_min = FB_HEIGHT;
	dirty_y_max = -1;

	if (mode == RMODE_TILES) {
		memset(cur_tiles, 0, sizeof(cur_tiles));
	} else if (mode == RMODE_PIXELS) {
		for (int i = 0; i < FB_HEIGHT; i++) {
			cur_spans[i].x_min = FB_WIDTH;
			cur_spans[i].x_max = 0;
		}
	}
}

void render_full_clear(void)
{
	memset(fb, 0, FB_PIXELS);
	memset(dirty, 0xFF, sizeof(dirty));
	dirty_y_min = 0;
	dirty_y_max = FB_HEIGHT - 1;
	memset(last_dirty, 0xFF, sizeof(last_dirty));
	last_y_min = 0;
	last_y_max = FB_HEIGHT - 1;

	memset(last_tiles, 0xFF, sizeof(last_tiles));
	memset(cur_tiles, 0xFF, sizeof(cur_tiles));

	for (int i = 0; i < FB_HEIGHT; i++) {
		last_spans[i].x_min = 0;
		last_spans[i].x_max = FB_WIDTH - 1;
		cur_spans[i].x_min = 0;
		cur_spans[i].x_max = FB_WIDTH - 1;
	}
}

/* ------------------------------------------------------------------ */
/*  Commit dirty state to shared memory                               */
/* ------------------------------------------------------------------ */

void render_commit_dirty(void)
{
	/* Row bitmap — always sent (all modes use y_min/y_max) */
	memcpy((void *)SHARED_DISP->dirty_rows, dirty, sizeof(dirty));
	memcpy((void *)SHARED_DISP->prev_dirty_rows, last_dirty, sizeof(last_dirty));

	int y_min = dirty_y_min;
	int y_max = dirty_y_max;
	if (last_y_min < y_min) y_min = last_y_min;
	if (last_y_max > y_max) y_max = last_y_max;
	SHARED_DISP->dirty_y_min = (int16_t)y_min;
	SHARED_DISP->dirty_y_max = (int16_t)y_max;

	if (mode == RMODE_TILES) {
		/* Merge current + last tiles for FLPR */
		for (int w = 0; w < TILE_WORDS; w++) {
			SHARED_DISP->dirty_tiles[w] = cur_tiles[w] | last_tiles[w];
		}
		/* Save current for next frame */
		memcpy(last_tiles, cur_tiles, sizeof(cur_tiles));
	} else if (mode == RMODE_PIXELS) {
		/* Merge current + last spans for FLPR */
		for (int y = y_min; y <= y_max && y < FB_HEIGHT; y++) {
			uint16_t cmin = cur_spans[y].x_min;
			uint16_t cmax = cur_spans[y].x_max;
			uint16_t lmin = last_spans[y].x_min;
			uint16_t lmax = last_spans[y].x_max;

			/* Union of current and last span */
			uint16_t rmin = (cmin < lmin) ? cmin : lmin;
			uint16_t rmax = (cmax > lmax) ? cmax : lmax;

			SHARED_DISP->dirty_spans[y].x_min = rmin;
			SHARED_DISP->dirty_spans[y].x_max = rmax;
		}
		/* Save current for next frame */
		memcpy(last_spans, cur_spans, sizeof(cur_spans));
	}

	/* Save row state for next frame */
	memcpy(last_dirty, dirty, sizeof(dirty));
	last_y_min = dirty_y_min;
	last_y_max = dirty_y_max;
}

/* ------------------------------------------------------------------ */
/*  Pixel                                                             */
/* ------------------------------------------------------------------ */

void render_pixel(int x, int y, uint8_t color)
{
	if ((unsigned)x < FB_WIDTH && (unsigned)y < FB_HEIGHT) {
		fb[y * FB_WIDTH + x] = color;
		mark_dirty(x, y);
	}
}

static inline void pixel_fast(int x, int y, uint8_t color)
{
	fb[y * FB_WIDTH + x] = color;
}

/* ------------------------------------------------------------------ */
/*  Line                                                              */
/* ------------------------------------------------------------------ */

void render_line(int x0, int y0, int x1, int y1, uint8_t color)
{
	int dx = abs(x1 - x0);
	int dy = -abs(y1 - y0);
	int sx = (x0 < x1) ? 1 : -1;
	int sy = (y0 < y1) ? 1 : -1;
	int err = dx + dy;

	for (;;) {
		if ((unsigned)x0 < FB_WIDTH && (unsigned)y0 < FB_HEIGHT) {
			pixel_fast(x0, y0, color);
			mark_dirty(x0, y0);
		}
		if (x0 == x1 && y0 == y1) break;
		int e2 = 2 * err;
		if (e2 >= dy) { err += dy; x0 += sx; }
		if (e2 <= dx) { err += dx; y0 += sy; }
	}
}

/* ------------------------------------------------------------------ */
/*  Circle                                                            */
/* ------------------------------------------------------------------ */

void render_circle(int cx, int cy, int r, uint8_t color)
{
	int x = r, y = 0, d = 1 - r;
	while (x >= y) {
		render_pixel(cx + x, cy + y, color);
		render_pixel(cx - x, cy + y, color);
		render_pixel(cx + x, cy - y, color);
		render_pixel(cx - x, cy - y, color);
		render_pixel(cx + y, cy + x, color);
		render_pixel(cx - y, cy + x, color);
		render_pixel(cx + y, cy - x, color);
		render_pixel(cx - y, cy - x, color);
		y++;
		if (d <= 0) { d += 2 * y + 1; }
		else { x--; d += 2 * (y - x) + 1; }
	}
}

static void hline(int x0, int x1, int y, uint8_t color)
{
	if ((unsigned)y >= FB_HEIGHT) return;
	if (x0 > x1) { int t = x0; x0 = x1; x1 = t; }
	if (x0 < 0) x0 = 0;
	if (x1 >= FB_WIDTH) x1 = FB_WIDTH - 1;
	if (x0 > x1) return;
	memset(&fb[y * FB_WIDTH + x0], color, x1 - x0 + 1);
	mark_row(y);
	if (mode == RMODE_TILES) {
		for (int x = x0; x <= x1; x += TILE_W) mark_tile(x, y);
		mark_tile(x1, y);
	} else if (mode == RMODE_PIXELS) {
		struct row_span *s = &cur_spans[y];
		if (x0 < s->x_min) s->x_min = x0;
		if (x1 > s->x_max) s->x_max = x1;
	}
}

void render_circle_filled(int cx, int cy, int r, uint8_t color)
{
	int x = r, y = 0, d = 1 - r;
	while (x >= y) {
		hline(cx - x, cx + x, cy + y, color);
		hline(cx - x, cx + x, cy - y, color);
		hline(cx - y, cx + y, cy + x, color);
		hline(cx - y, cx + y, cy - x, color);
		y++;
		if (d <= 0) { d += 2 * y + 1; }
		else { x--; d += 2 * (y - x) + 1; }
	}
}

/* ------------------------------------------------------------------ */
/*  Polygon                                                           */
/* ------------------------------------------------------------------ */

void render_polygon(const int *vx, const int *vy, int count, uint8_t color)
{
	int i;
	for (i = 0; i < count - 1; i++) {
		render_line(vx[i], vy[i], vx[i + 1], vy[i + 1], color);
	}
	render_line(vx[i], vy[i], vx[0], vy[0], color);
}

/* ------------------------------------------------------------------ */
/*  Text                                                              */
/* ------------------------------------------------------------------ */

void render_char(int x, int y, char ch, uint8_t color)
{
	if (ch < 32 || ch > 126) return;
	if (x >= FB_WIDTH || y >= FB_HEIGHT || x + 8 <= 0 || y + 8 <= 0) return;

	const uint8_t *glyph = font_8x8[(int)ch - 32];

	for (int row = 0; row < 8; row++) {
		int py = y + row;
		if ((unsigned)py >= FB_HEIGHT) continue;
		uint8_t bits = glyph[row];
		if (!bits) continue;
		for (int col = 0; col < 8; col++) {
			if (bits & (0x80 >> col)) {
				int px = x + col;
				if ((unsigned)px < FB_WIDTH) {
					pixel_fast(px, py, color);
					mark_dirty(px, py);
				}
			}
		}
	}
}

void render_string(int x, int y, const char *str, uint8_t color)
{
	while (*str) {
		render_char(x, y, *str, color);
		x += 8;
		str++;
	}
}

void render_string_centered(int y, const char *str, uint8_t color)
{
	int len = 0;
	const char *s = str;
	while (*s++) len++;
	render_string((FB_WIDTH - len * 8) / 2, y, str, color);
}

void render_number(int x, int y, int num, uint8_t color)
{
	char buf[12];
	int i = 0, neg = 0;

	if (num < 0) { neg = 1; num = -num; }
	if (num == 0) { buf[i++] = '0'; }
	else { while (num > 0) { buf[i++] = '0' + (num % 10); num /= 10; } }
	if (neg) { buf[i++] = '-'; }

	for (int j = i - 1; j >= 0; j--) {
		render_char(x, y, buf[j], color);
		x += 8;
	}
}

void render_number_centered(int y, int num, uint8_t color)
{
	int n = (num < 0) ? -num : num;
	int digits = (n == 0) ? 1 : 0;
	while (n > 0) { digits++; n /= 10; }
	if (num < 0) digits++;
	render_number((FB_WIDTH - digits * 8) / 2, y, num, color);
}

void render_sprite(int x, int y, const uint8_t *data, int w, int h)
{
	for (int row = 0; row < h; row++) {
		int py = y + row;
		if ((unsigned)py >= FB_HEIGHT) { data += w; continue; }
		for (int col = 0; col < w; col++) {
			uint8_t c = *data++;
			if (c != 0) {  /* 0 = transparent, skip */
				int px = x + col;
				if ((unsigned)px < FB_WIDTH) {
					fb[py * FB_WIDTH + px] = c;
					mark_dirty(px, py);
				}
			}
		}
	}
}
```

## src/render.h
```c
#ifndef RENDER_H
#define RENDER_H

#include <stdint.h>
#include "shared_display.h"

void render_init(uint8_t *framebuffer);
void render_set_mode(uint8_t mode);  /* RMODE_ROWS, RMODE_TILES, RMODE_PIXELS */
void render_clear(void);
void render_full_clear(void);
void render_commit_dirty(void);

void render_pixel(int x, int y, uint8_t color);
void render_line(int x0, int y0, int x1, int y1, uint8_t color);
void render_circle(int cx, int cy, int r, uint8_t color);
void render_circle_filled(int cx, int cy, int r, uint8_t color);
void render_polygon(const int *vx, const int *vy, int count, uint8_t color);
void render_char(int x, int y, char ch, uint8_t color);
void render_string(int x, int y, const char *str, uint8_t color);
void render_string_centered(int y, const char *str, uint8_t color);
void render_number(int x, int y, int num, uint8_t color);
void render_number_centered(int y, int num, uint8_t color);

/* Draw a sprite with transparency (index 0 = skip) */
void render_sprite(int x, int y, const uint8_t *data, int w, int h);

#endif /* RENDER_H */
```
